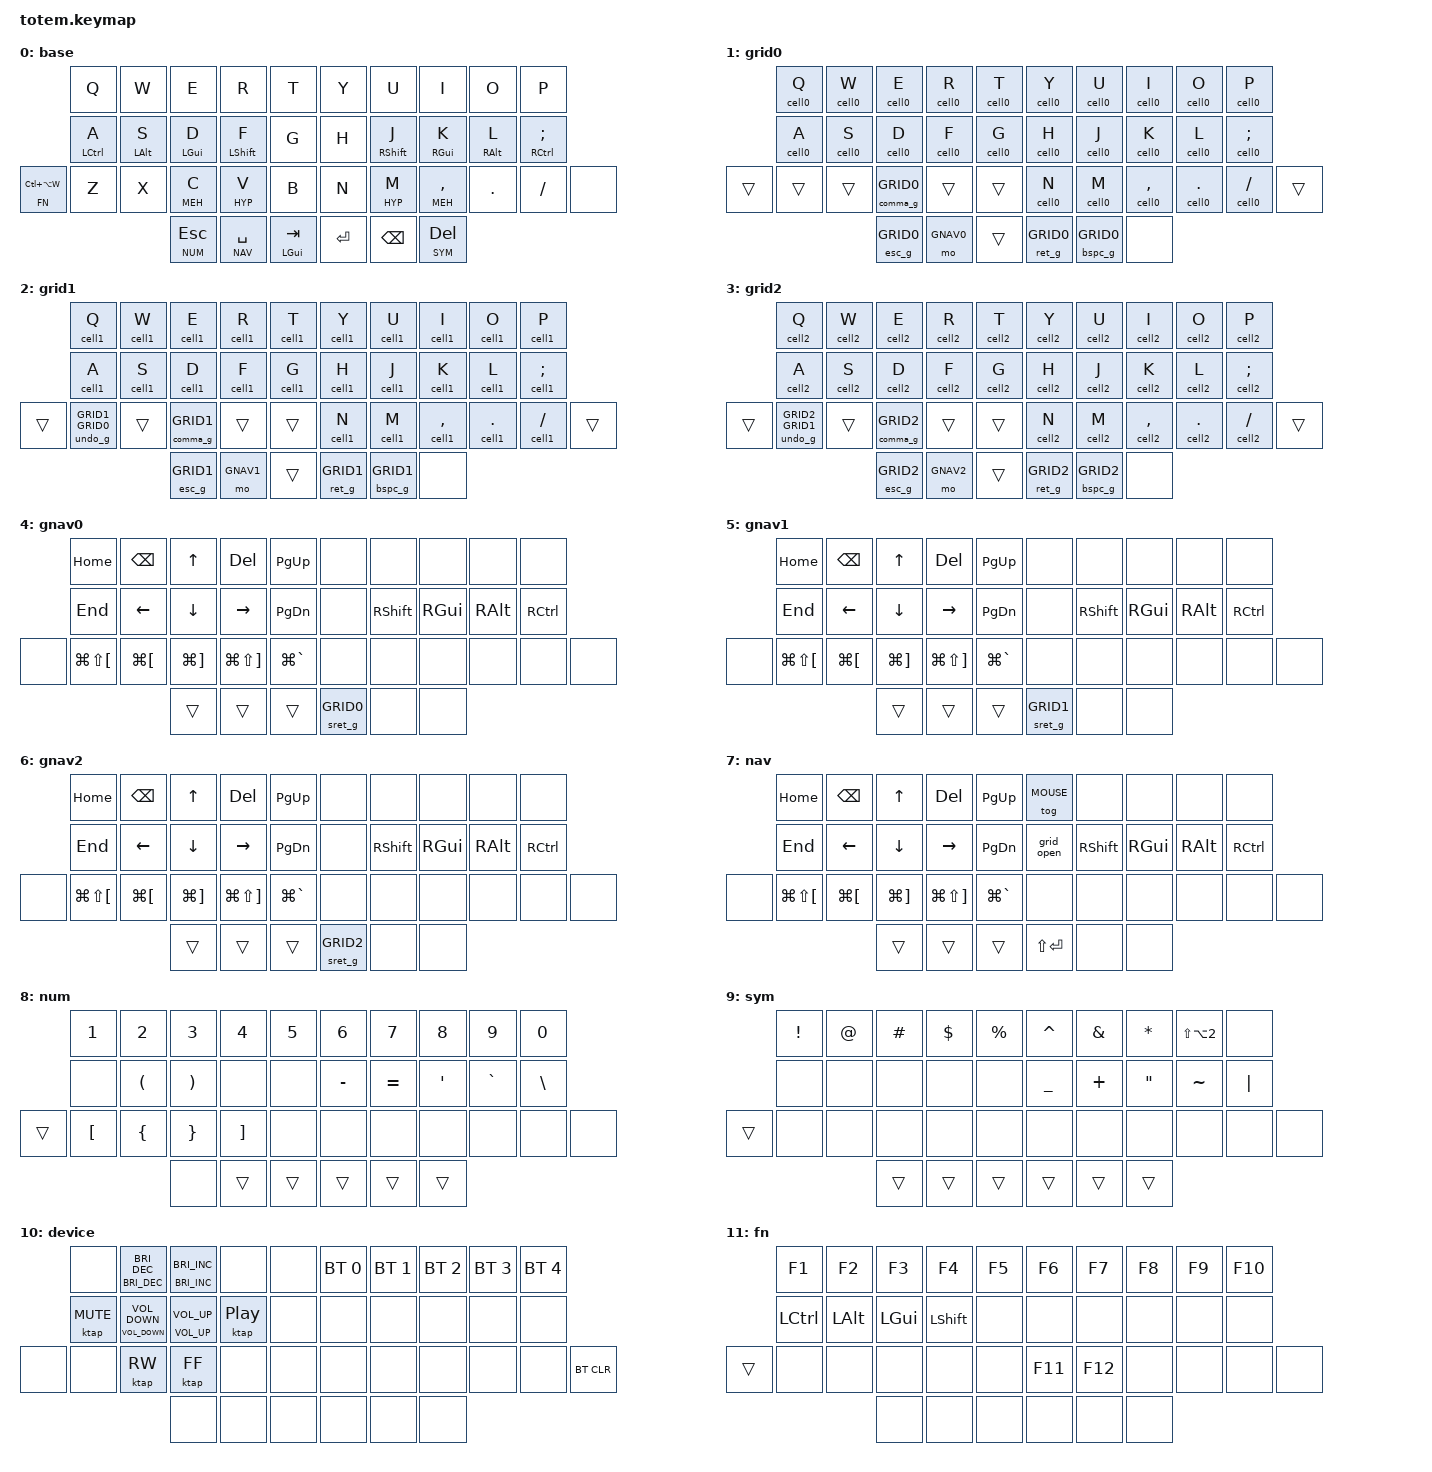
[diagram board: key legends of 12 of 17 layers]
//
//                                                        ▀▀▀▀▀     ▀▀▀▀▀          ▀▀█▀▀
//                                                        ▄▀▀▀▄  ▄  ▄▀▀▀▄  ▄  ▄▀▀▀▄  █  ▄▀▀▀▄
//                                                        █   █  █  █   █  █  █   █  █  █   █
//                                                         ▀▀▀   █   ▀▀▀   █   ▀▀▀   ▀   ▀▀▀
//                                                               █      ▄▄▄█▄▄▄    █   █
//                                                               ▀      █  █  █     █▄█
//                                                             ▀▀▀▀▀    █  █  █      ▀
//                                                                      ▀  ▀  ▀
//
// ▄▄▄▄▄▄▄▄▄▄▄▄▄▄▄▄▄▄▄▄▄▄▄▄▄▄▄▄▄▄▄▄▄▄▄▄▄▄▄▄▄▄▄▄▄▄▄▄▄▄▄▄▄▄▄▄▄▄▄▄▄▄▄▄▄▄▄▄▄▄▄▄▄▄▄▄▄▄▄▄▄▄▄▄▄▄▄▄▄▄▄▄▄▄▄▄▄▄▄▄▄▄▄▄▄▄▄▄▄▄▄▄▄▄▄▄▄▄▄▄▄▄▄▄▄▄▄▄▄▄▄▄▄▄▄▄▄▄▄▄▄▄▄▄▄▄▄▄▄

#include <behaviors.dtsi>
#include <dt-bindings/zmk/bt.h>
#include <dt-bindings/zmk/keys.h>
#include <dt-bindings/zmk/modifiers.h>

// Pointer speed. Firmware default is 600, which crawls; scroll's default 10
// was too slow on-device and 25 too fast.
#define ZMK_POINTING_DEFAULT_MOVE_VAL 1500
#define ZMK_POINTING_DEFAULT_SCRL_VAL 16
#include <dt-bindings/zmk/pointing.h>
#include <zephyr/dt-bindings/input/input-event-codes.h>
#include <input/processors.dtsi>

#define BASE  0
#define GRID0 1
#define GRID1 2
#define GRID2 3
#define GNAV0 4
#define GNAV1 5
#define GNAV2 6
#define NAV   7
#define NUM   8
#define SYM   9
#define DEV   10
#define FN    11
#define ACCENT 12
#define MOUSE   13
#define PRECISE 14
#define SCROLL  15
#define FAST    16

// Hyper = cmd+ctrl+alt+shift, Meh = ctrl+alt+shift.
// No app claims these, so they are safe for global hotkeys.
#define HYP LS(LC(LA(LGUI)))
#define MEH LS(LC(LALT))

// TOTEM key positions, 0-37, in keymap order.
#define KEYS_L  0  1  2  3  4 10 11 12 13 14 20 21 22 23 24 25
#define KEYS_R  5  6  7  8  9 15 16 17 18 19 26 27 28 29 30 31
#define THUMBS 32 33 34 35 36 37

&mt {
    flavor = "balanced";
    tapping-term-ms = <200>;
    // 300 gives an easy tap-then-hold window for auto-repeating tab
    // (cmd+tab cycling). Only the tab thumb uses &mt.
    quick-tap-ms = <300>;
};

// Ramp to full pointer speed over half a second, so a short tap nudges a few
// pixels and a held key crosses the screen. exponent 1 = linear ramp.
// &msc is left at its defaults, which already do not accelerate.
&mmv {
    time-to-max-speed-ms = <500>;
    acceleration-exponent = <1>;
};

// Fast is a scaler on the pointer's event stream, not a set of faster keys:
// holding the fast thumb doubles whatever &mmv is already emitting, so it
// engages mid-hold -- press fast while moving and the cursor speeds up
// instantly, release and it slows. (A key's binding is locked at press time,
// so the old separate-bindings fast only applied to re-presses.)
&mmv_input_listener {
    fast {
        layers = <FAST>;
        input-processors = <&zip_xy_scaler 2 1>;
    };
};

/ {
    behaviors {
        // A second pointer instance with acceleration switched off, used only
        // by the precise tier: a ramped "precise" barely moves on a tap, so
        // its 150 must land on the first report. Fast is not a binding at all
        // anymore -- it is the x2 scaler on &mmv_input_listener above.
        // exponent 0 makes time-to-max-speed-ms inert; it matches the shape
        // ZMK ships for &msc.
        mmv_flat: mmv_flat {
            compatible = "zmk,behavior-input-two-axis";
            #binding-cells = <1>;
            x-input-code = <INPUT_REL_X>;
            y-input-code = <INPUT_REL_Y>;
            time-to-max-speed-ms = <300>;
            acceleration-exponent = <0>;
        };

        // Mouse layer's space thumb: tap is a left click that stays in mouse
        // mode, hold is the scroll layer. hold-preferred so scrolling with
        // e/s/d/f engages immediately; only a lone crisp tap clicks.
        click_scroll: click_scroll {
            compatible = "zmk,behavior-hold-tap";
            #binding-cells = <2>;
            flavor = "hold-preferred";
            tapping-term-ms = <200>;
            bindings = <&mo>, <&mkp>;
        };

        // Mouse layer's esc thumb: tap exits to base (like Esc ends a neru
        // mode), hold is the precise tier. hold-preferred so moving with
        // e/s/d/f while held resolves precise immediately.
        exit_precise: exit_precise {
            compatible = "zmk,behavior-hold-tap";
            #binding-cells = <2>;
            flavor = "hold-preferred";
            tapping-term-ms = <200>;
            bindings = <&mo>, <&to>;
        };

        // Timeless home row mods, per urob / ZMK docs.
        // A mod only fires on cross-hand or thumb follow-ups, and never
        // mid-typing-stream. Same-hand rolls always resolve as taps.
        hml: home_row_mod_left {
            compatible = "zmk,behavior-hold-tap";
            #binding-cells = <2>;
            flavor = "balanced";
            tapping-term-ms = <280>;
            quick-tap-ms = <175>;
            require-prior-idle-ms = <100>;
            bindings = <&kp>, <&kp>;
            hold-trigger-key-positions = <KEYS_R THUMBS>;
            hold-trigger-on-release;
        };

        hmr: home_row_mod_right {
            compatible = "zmk,behavior-hold-tap";
            #binding-cells = <2>;
            flavor = "balanced";
            tapping-term-ms = <280>;
            quick-tap-ms = <175>;
            require-prior-idle-ms = <100>;
            bindings = <&kp>, <&kp>;
            hold-trigger-key-positions = <KEYS_L THUMBS>;
            hold-trigger-on-release;
        };

        // One step per press however long it is held; tap then press-and-hold
        // within quick-tap-ms keeps the key down so macOS repeats it. A tap
        // releases before tapping-term-ms, which must stay below macOS
        // InitialKeyRepeat (180 ms) or a slow tap repeats.
        tap_rep: tap_rep {
            compatible = "zmk,behavior-hold-tap";
            #binding-cells = <2>;
            flavor = "tap-preferred";
            tapping-term-ms = <150>;
            quick-tap-ms = <300>;
            bindings = <&ktap>, <&kp>;
        };
    };

    // A two-axis behavior emits movement onto its own virtual input device;
    // without a listener routing that device into the HID pipeline the events
    // go nowhere and the keys silently do nothing -- precise/fast pressed
    // fine and moved nothing. ZMK pairs its built-in &mmv with exactly this
    // node (app/dts/behaviors/mouse_move.dtsi); a second instance needs its
    // own.
    mmv_flat_input_listener {
        compatible = "zmk,input-listener";
        device = <&mmv_flat>;
    };

    macros {
        // Click and leave the pointer layer in one tap. This is the mouse
        // layer's default right-thumb click, mirroring neru's own default,
        // Space = ["action left_click", "idle"]. Staying in mode is the
        // exception, reached by holding scroll, the left thumb's middle
        // position (see the scroll layer, which overrides these three
        // positions back to a plain, non-exiting &mkp) -- neru's own
        // exception is the same shape, Shift+Space = "action left_click"
        // with no idle. Release before the layer change, or the button
        // sticks.
        lclk_exit: lclk_exit {
            compatible = "zmk,behavior-macro";
            #binding-cells = <0>;
            bindings = <&macro_tap &mkp LCLK>, <&macro_tap &to BASE>;
        };

        rclk_exit: rclk_exit {
            compatible = "zmk,behavior-macro";
            #binding-cells = <0>;
            bindings = <&macro_tap &mkp RCLK>, <&macro_tap &to BASE>;
        };

        mclk_exit: mclk_exit {
            compatible = "zmk,behavior-macro";
            #binding-cells = <0>;
            bindings = <&macro_tap &mkp MCLK>, <&macro_tap &to BASE>;
        };

        // Fixed-length tap whatever the physical hold time. macOS auto-repeats
        // media keys held past InitialKeyRepeat (180 ms here), and a repeated
        // mute or play/pause toggles straight back.
        ktap: ktap {
            compatible = "zmk,behavior-macro-one-param";
            #binding-cells = <1>;
            wait-ms = <0>;
            tap-ms = <30>;
            bindings = <&macro_param_1to1>, <&macro_tap &kp MACRO_PLACEHOLDER>;
        };

        // Firmware-tracked neru grid, as a depth ladder: GRID0/1/2 mirror the
        // grid's selection depth. Cell letters step up a level; the 3rd press
        // matches neru's auto-click+exit and drops everything. z walks back
        // down (neru binds z = undo one level). Esc / ret / bspc / comma
        // close from any level. Desync paths (nav shift+click, tab-tap undo,
        // trackpad clicks, manual V+H trigger) recover with one Esc tap.
        cell0: cell0 {
            compatible = "zmk,behavior-macro-one-param";
            #binding-cells = <1>;
            wait-ms = <0>;
            tap-ms = <5>;
            bindings = <&macro_param_1to1>, <&kp MACRO_PLACEHOLDER>, <&tog GRID0>, <&tog GRID1>;
        };

        cell1: cell1 {
            compatible = "zmk,behavior-macro-one-param";
            #binding-cells = <1>;
            wait-ms = <0>;
            tap-ms = <5>;
            bindings = <&macro_param_1to1>, <&kp MACRO_PLACEHOLDER>, <&tog GRID1>, <&tog GRID2>;
        };

        cell2: cell2 {
            compatible = "zmk,behavior-macro-one-param";
            #binding-cells = <1>;
            wait-ms = <0>;
            tap-ms = <5>;
            bindings = <&macro_param_1to1>, <&kp MACRO_PLACEHOLDER>, <&tog GRID2>;
        };

        esc_g: esc_g {
            compatible = "zmk,behavior-macro-one-param";
            #binding-cells = <1>;
            wait-ms = <0>;
            tap-ms = <5>;
            bindings = <&kp ESC>, <&macro_param_1to1>, <&tog MACRO_PLACEHOLDER>;
        };

        ret_g: ret_g {
            compatible = "zmk,behavior-macro-one-param";
            #binding-cells = <1>;
            wait-ms = <0>;
            tap-ms = <5>;
            bindings = <&kp RET>, <&macro_param_1to1>, <&tog MACRO_PLACEHOLDER>;
        };

        bspc_g: bspc_g {
            compatible = "zmk,behavior-macro-one-param";
            #binding-cells = <1>;
            wait-ms = <0>;
            tap-ms = <5>;
            bindings = <&kp BSPC>, <&macro_param_1to1>, <&tog MACRO_PLACEHOLDER>;
        };

        // the hop: close neru, land in firmware mouse mode -- and back.
        comma_g: comma_g {
            compatible = "zmk,behavior-macro-one-param";
            #binding-cells = <1>;
            wait-ms = <0>;
            tap-ms = <5>;
            bindings = <&kp ESC>, <&macro_param_1to1>, <&tog MACRO_PLACEHOLDER>, <&tog MOUSE>;
        };

        undo_g: undo_g {
            compatible = "zmk,behavior-macro-two-param";
            #binding-cells = <2>;
            wait-ms = <0>;
            tap-ms = <5>;
            bindings = <&kp Z>, <&macro_param_1to1>, <&tog MACRO_PLACEHOLDER>, <&macro_param_2to1>, <&tog MACRO_PLACEHOLDER>;
        };

        // shift+click that the ladder can see: LS(RET) plus the level drop.
        sret_g: sret_g {
            compatible = "zmk,behavior-macro-one-param";
            #binding-cells = <1>;
            wait-ms = <0>;
            tap-ms = <5>;
            bindings = <&kp LS(RET)>, <&macro_param_1to1>, <&tog MACRO_PLACEHOLDER>;
        };

        grid_open: grid_open {
            compatible = "zmk,behavior-macro";
            #binding-cells = <0>;
            wait-ms = <0>;
            tap-ms = <5>;
            bindings = <&kp LS(LC(LA(LG(H))))>, <&tog GRID0>;
        };

        mouse_to_grid: mouse_to_grid {
            compatible = "zmk,behavior-macro";
            #binding-cells = <0>;
            wait-ms = <0>;
            tap-ms = <5>;
            bindings = <&tog MOUSE>, <&kp LS(LC(LA(LG(H))))>, <&tog GRID0>;
        };

        // Drag lock. macro_press holds the button without releasing it, so both
        // hands stay free to move and scroll mid-drag; drag_off drops it. Only
        // worth reaching for on long drags -- holding the LCLK thumb and moving
        // with the same hand's fingers is a real drag already.
        drag_on: drag_on {
            compatible = "zmk,behavior-macro";
            #binding-cells = <0>;
            bindings = <&macro_press &mkp LCLK>;
        };

        drag_off: drag_off {
            compatible = "zmk,behavior-macro";
            #binding-cells = <0>;
            bindings = <&macro_release &mkp LCLK>;
        };

        // macOS dead keys via option (e=acute, `=grave, i=circumflex, u=trema).
        // Needs keyboard type = ANSI, else option+` sends a section sign.
        fr_e_acute: fr_e_acute {
            compatible = "zmk,behavior-macro";
            #binding-cells = <0>;
            bindings = <&macro_tap &kp LA(E)>, <&macro_tap &kp E>;
        };

        fr_e_grave: fr_e_grave {
            compatible = "zmk,behavior-macro";
            #binding-cells = <0>;
            bindings = <&macro_tap &kp LA(GRAVE)>, <&macro_tap &kp E>;
        };

        fr_a_grave: fr_a_grave {
            compatible = "zmk,behavior-macro";
            #binding-cells = <0>;
            bindings = <&macro_tap &kp LA(GRAVE)>, <&macro_tap &kp A>;
        };

        fr_u_grave: fr_u_grave {
            compatible = "zmk,behavior-macro";
            #binding-cells = <0>;
            bindings = <&macro_tap &kp LA(GRAVE)>, <&macro_tap &kp U>;
        };

        fr_circumflex: fr_circumflex {
            compatible = "zmk,behavior-macro";
            #binding-cells = <0>;
            bindings = <&macro_tap &kp LA(I)>;
        };

        fr_trema: fr_trema {
            compatible = "zmk,behavior-macro";
            #binding-cells = <0>;
            bindings = <&macro_tap &kp LA(U)>;
        };
    };

    combos {
        compatible = "zmk,combos";

        // F + J together -> caps lock. Base layer only, so it cannot fire
        // while a layer is held. Short timeout to avoid catching fast typing.
        combo_caps {
            timeout-ms = <40>;
            require-prior-idle-ms = <120>;
            key-positions = <13 16>;   // F and J
            bindings = <&kp CAPS>;
            layers = <BASE>;
        };

        // z + x -> sticky accent layer. Not a digraph, both keys plain.
        combo_accent {
            timeout-ms = <40>;
            require-prior-idle-ms = <120>;
            key-positions = <21 22>;   // Z and X
            bindings = <&sl ACCENT>;
            layers = <BASE>;
        };
    };

    keymap {
        compatible = "zmk,keymap";

        // Mods, weakest finger outward: ctrl - alt - cmd - shift
        // Cmd sits on the middle finger because it is the most used
        // modifier on macOS. Ctrl is on the pinky because it is the least.
        // num key taps ctrl+alt+w for Wispr Flow (its hotkey caps at 3 keys).
        base {
            bindings = <
        &kp Q         &kp W        &kp E        &kp R         &kp T      &kp Y      &kp U         &kp I        &kp O        &kp P
        &hml LCTRL A  &hml LALT S  &hml LGUI D  &hml LSHFT F  &kp G      &kp H      &hmr RSHFT J  &hmr RGUI K  &hmr RALT L  &hmr RCTRL SEMI
&lt FN LC(LA(W))  &kp Z   &kp X        &hml MEH C   &hml HYP V    &kp B      &kp N      &hmr HYP M    &hmr MEH COMMA &kp DOT    &kp FSLH        &none
                                   &lt NUM ESC   &lt NAV SPACE  &mt LGUI TAB &kp RET    &kp BSPC      &lt SYM DEL
            >;
        };

        // Depth ladder tracking neru's grid, below nav in priority. Cell
        // letters advance a level and the 3rd press (= neru's auto-click)
        // drops everything back to base. z walks down a level (neru undo);
        // esc / ret / bspc / comma close from any depth; comma lands in
        // firmware mouse mode. Space still holds nav through these, so
        // space+esdf scroll and space+ret shift+click keep working.
        grid0 {
            bindings = <
        &cell0 Q   &cell0 W   &cell0 E   &cell0 R   &cell0 T      &cell0 Y   &cell0 U   &cell0 I   &cell0 O   &cell0 P
        &cell0 A   &cell0 S   &cell0 D   &cell0 F   &cell0 G      &cell0 H   &cell0 J   &cell0 K   &cell0 L   &cell0 SEMI
&trans  &trans     &trans      &comma_g GRID0   &trans   &trans      &cell0 N   &cell0 M   &cell0 COMMA  &cell0 DOT  &cell0 FSLH  &trans
                              &esc_g GRID0  &mo GNAV0  &trans      &ret_g GRID0  &bspc_g GRID0  &none
            >;
        };

        grid1 {
            bindings = <
        &cell1 Q   &cell1 W   &cell1 E   &cell1 R   &cell1 T      &cell1 Y   &cell1 U   &cell1 I   &cell1 O   &cell1 P
        &cell1 A   &cell1 S   &cell1 D   &cell1 F   &cell1 G      &cell1 H   &cell1 J   &cell1 K   &cell1 L   &cell1 SEMI
&trans  &undo_g GRID1 GRID0  &trans      &comma_g GRID1   &trans   &trans      &cell1 N   &cell1 M   &cell1 COMMA  &cell1 DOT  &cell1 FSLH  &trans
                              &esc_g GRID1  &mo GNAV1  &trans      &ret_g GRID1  &bspc_g GRID1  &none
            >;
        };

        grid2 {
            bindings = <
        &cell2 Q   &cell2 W   &cell2 E   &cell2 R   &cell2 T      &cell2 Y   &cell2 U   &cell2 I   &cell2 O   &cell2 P
        &cell2 A   &cell2 S   &cell2 D   &cell2 F   &cell2 G      &cell2 H   &cell2 J   &cell2 K   &cell2 L   &cell2 SEMI
&trans  &undo_g GRID2 GRID1  &trans      &comma_g GRID2   &trans   &trans      &cell2 N   &cell2 M   &cell2 COMMA  &cell2 DOT  &cell2 FSLH  &trans
                              &esc_g GRID2  &mo GNAV2  &trans      &ret_g GRID2  &bspc_g GRID2  &none
            >;
        };

        // nav mirror while grid depth 0 is active: same arrows/pages/mods,
        // but ret drops the ladder with its shift+click, and the mouse toggle
        // and grid trigger are blanked (both would ghost the ladder).
        gnav0 {
            bindings = <
             &kp HOME     &kp BACKSPACE  &kp UP     &kp DELETE  &kp PG_UP     &none  &none  &none  &none  &none
             &kp END      &kp LEFT       &kp DOWN   &kp RIGHT   &kp PG_DN     &none  &kp RSHFT  &kp RGUI  &kp RALT  &kp RCTRL
&none        &kp LG(LS(LBKT)) &kp LG(LBKT) &kp LG(RBKT) &kp LG(LS(RBKT)) &kp LG(GRAVE)  &none  &none      &none     &none     &none      &none
                                         &trans     &trans      &trans        &sret_g GRID0  &none      &none
            >;
        };

        // nav mirror while grid depth 1 is active: same arrows/pages/mods,
        // but ret drops the ladder with its shift+click, and the mouse toggle
        // and grid trigger are blanked (both would ghost the ladder).
        gnav1 {
            bindings = <
             &kp HOME     &kp BACKSPACE  &kp UP     &kp DELETE  &kp PG_UP     &none  &none  &none  &none  &none
             &kp END      &kp LEFT       &kp DOWN   &kp RIGHT   &kp PG_DN     &none  &kp RSHFT  &kp RGUI  &kp RALT  &kp RCTRL
&none        &kp LG(LS(LBKT)) &kp LG(LBKT) &kp LG(RBKT) &kp LG(LS(RBKT)) &kp LG(GRAVE)  &none  &none      &none     &none     &none      &none
                                         &trans     &trans      &trans        &sret_g GRID1  &none      &none
            >;
        };

        // nav mirror while grid depth 2 is active: same arrows/pages/mods,
        // but ret drops the ladder with its shift+click, and the mouse toggle
        // and grid trigger are blanked (both would ghost the ladder).
        gnav2 {
            bindings = <
             &kp HOME     &kp BACKSPACE  &kp UP     &kp DELETE  &kp PG_UP     &none  &none  &none  &none  &none
             &kp END      &kp LEFT       &kp DOWN   &kp RIGHT   &kp PG_DN     &none  &kp RSHFT  &kp RGUI  &kp RALT  &kp RCTRL
&none        &kp LG(LS(LBKT)) &kp LG(LBKT) &kp LG(RBKT) &kp LG(LS(RBKT)) &kp LG(GRAVE)  &none  &none      &none     &none     &none      &none
                                         &trans     &trans      &trans        &sret_g GRID2  &none      &none
            >;
        };

        // Left hand keeps arrows usable one-handed with the right hand on
        // the trackpad; right home row carries plain mods for cmd+arrow.
        // x/c = history back/forward, v/b = prev/next tab. Device reuses
        // x/c for rewind/fast-forward.
        //
        // h toggles the pointer layer, which is a mode, not a hold. The neru
        // grid is launched by typing its hyper+h hotkey directly: hold v
        // (hyper) + h. Cross-hand, so the home-row hold resolves; m (the
        // other hyper) is same-hand with h and will not.
        //
        // The ret thumb sends shift+enter: with the grid open, plain thumbs
        // click-and-exit (neru binds Enter/Backspace), and holding this nav
        // thumb + ret is shift+click (neru injects the shift via --modifier).
        // cmd+click is the tab thumb's cmd mod-tap held + plain ret.
        nav {
            bindings = <
             &kp HOME     &kp BACKSPACE  &kp UP     &kp DELETE  &kp PG_UP     &tog MOUSE  &none  &none  &none  &none
             &kp END      &kp LEFT       &kp DOWN   &kp RIGHT   &kp PG_DN     &grid_open   &kp RSHFT  &kp RGUI  &kp RALT  &kp RCTRL
&none        &kp LG(LS(LBKT)) &kp LG(LBKT) &kp LG(RBKT) &kp LG(LS(RBKT)) &kp LG(GRAVE)  &none  &none      &none     &none     &none      &none
                                         &trans     &trans      &trans        &kp LS(RET)  &none  &none
            >;
        };

        // Numbers across the top row like a normal keyboard; qwerty's
        // punctuation strip (- = ' ` \) on the right home row in qwerty
        // order. Brackets keep their spots; { } slide down beside ( ) since
        // the numbers evicted them; euro next door. Thumbs transparent so
        // ret/bspc work mid-number. Mod chords (zoom cmd+=, screenshot
        // shift+cmd+4) pre-hold the base home-row mods, then num.
        num {
            bindings = <
           &kp N1         &kp N2                &kp N3                 &kp N4            &kp N5            &kp N6      &kp N7    &kp N8     &kp N9    &kp N0
           &none          &kp LEFT_PARENTHESIS  &kp RIGHT_PARENTHESIS  &none             &none             &kp MINUS   &kp EQUAL &kp APOS   &kp GRAVE &kp BSLH
&trans     &kp LBKT       &kp LEFT_BRACE        &kp RIGHT_BRACE        &kp RBKT          &none             &none       &none     &none      &none     &none     &none
                                                &none                  &trans            &trans            &trans      &trans    &trans
            >;
        };

        // Shifted mirror of num, same positions: sym(key) = shift(num(key)),
        // no exceptions. Own thumb-hold on Del (tap Del, hold Sym),
        // independent of whether num is also held.
        sym {
            bindings = <
        &kp EXCLAMATION &kp AT_SIGN     &kp HASH  &kp DOLLAR  &kp PERCENT    &kp CARET  &kp AMPERSAND  &kp ASTERISK  &kp LS(LA(N2))  &none
        &none      &none            &none             &none              &none    &kp UNDERSCORE   &kp PLUS   &kp DOUBLE_QUOTES  &kp TILDE  &kp PIPE
&trans     &none      &none            &none             &none              &none    &none            &none      &none              &none      &none      &none
                                     &trans           &trans            &trans   &trans           &trans          &trans
            >;
        };

        device {
            bindings = <
       &none         &tap_rep C_BRIGHTNESS_DEC C_BRIGHTNESS_DEC  &tap_rep C_BRIGHTNESS_INC C_BRIGHTNESS_INC  &none               &none    &bt BT_SEL 0  &bt BT_SEL 1  &bt BT_SEL 2  &bt BT_SEL 3  &bt BT_SEL 4
       &ktap K_MUTE  &tap_rep C_VOLUME_DOWN C_VOLUME_DOWN        &tap_rep C_VOLUME_UP C_VOLUME_UP            &ktap C_PLAY_PAUSE  &none    &none         &none         &none         &none         &none
&none  &none         &ktap C_RW              &ktap C_FF              &none               &none    &none         &none         &none         &none         &none         &bt BT_CLR
                                         &none                 &none             &none    &none         &none         &none
            >;
        };

        // Function keys, held with the left outer pinky. Left home row carries
        // plain mods so cmd+f-key and shift+f-key work while the layer is held.
        fn {
            bindings = <
        &kp F1     &kp F2     &kp F3     &kp F4     &kp F5      &kp F6  &kp F7  &kp F8  &kp F9  &kp F10
        &kp LCTRL  &kp LALT   &kp LGUI   &kp LSHFT  &none       &none   &none   &none   &none   &none
&trans  &none      &none      &none      &none      &none       &kp F11 &kp F12 &none   &none   &none   &none
                              &none      &none      &none       &none   &none   &none
            >;
        };

        // Reached via the z+x sticky combo: one chord, one tap, no holds.
        // i/y arm the circumflex/trema dead keys instead of a fixed letter.
        accent {
            bindings = <
&trans       &trans  &fr_e_acute  &trans      &trans   &fr_trema  &fr_u_grave  &fr_circumflex  &trans  &trans
&fr_a_grave  &trans  &fr_e_grave  &trans      &trans   &trans     &trans       &trans          &trans  &trans
&trans       &trans  &trans       &kp LA(C)   &trans   &trans     &trans       &trans          &trans  &trans  &trans  &trans
                                  &trans      &trans   &trans     &trans       &trans          &trans
            >;
        };

        // Firmware pointer, arranged after miryoku's mouse layer: one hand owns
        // the pointer, the other owns the modifiers, so every modified action
        // is a cross-hand chord and nothing contorts.
        //
        // Miryoku's rule is that mouse movement mirrors cursor navigation, and
        // nav here is left-handed, so the pointer is too: move on e/s/d/f, the
        // exact inverted-T nav uses for arrows.
        //
        // Clicks are on the right thumbs, left/right/middle outward from
        // center: left click nearest the fingers since it is the one held for
        // drag, middle click outermost since it is rarest. They exit the
        // layer by default -- aim, click, done, mirroring neru's own default
        // (Space = ["action left_click", "idle"]). Holding scroll (the left
        // thumb's middle position) and clicking is the exception that stays
        // in mode, mirroring neru's Shift+Space (click with no idle) -- see
        // the scroll layer, which overrides these three positions back to a
        // plain, non-exiting &mkp. Esc is dropped: it was only reachable one
        // thumb at a time anyway, since scroll occupies the thumb Esc used
        // to sit on.
        //
        // Left thumbs are slow / scroll / fast, one hold each -- a single
        // thumb only ever does one job at a time, so scroll lives on its own
        // thumb rather than a separate key on row3. See precise/scroll/fast
        // below for why each is a held layer rather than a modifier.
        //
        // Right home row is plain mods, same order as base. That is what makes
        // ctrl+scroll (zoom in Figma and browsers), shift+click, and cmd+click
        // work without the pointer hand leaving home position.
        //
        // Miryoku holds this layer with an opposite-hand thumb; all three left
        // thumbs are already committed here, so it stays a toggle off nav's h,
        // exited from the same position.
        mouse {
            bindings = <
        &none      &none           &mmv MOVE_UP    &none            &none      &none    &none    &none     &none     &none
        &none      &mmv MOVE_LEFT  &mmv MOVE_DOWN  &mmv MOVE_RIGHT  &none      &none    &kp RSHFT &kp RGUI  &kp RALT  &kp RCTRL
&trans  &drag_on   &drag_off       &mouse_to_grid  &none            &none      &none    &none     &none     &none     &none      &none
                                   &exit_precise PRECISE BASE  &click_scroll SCROLL LCLK  &mo FAST   &lclk_exit  &rclk_exit  &mclk_exit
            >;
        };

        // Speed tiers on e/s/d/f, held from the left thumbs' outer two
        // positions. Held layers rather than mod-morphs for the same reason
        // as scroll: a real modifier would cost mod+drag.
        //
        // &mmv_flat, not &mmv: no ramp, so the value lands on the first
        // report. That is the whole point of a tier -- a ramped tier is just
        // the normal key with a different ceiling.
        precise {
            bindings = <
        &trans  &trans                  &mmv_flat MOVE_Y(-150)   &trans                  &trans   &trans  &trans  &trans  &trans  &trans
        &trans  &mmv_flat MOVE_X(-150)  &mmv_flat MOVE_Y(150)    &mmv_flat MOVE_X(150)   &trans   &trans  &trans  &trans  &trans  &trans
&trans  &trans  &trans                  &trans                   &trans                  &trans   &trans  &trans  &trans  &trans  &trans  &trans
                                        &trans                   &trans                  &trans   &trans  &trans  &trans
            >;
        };

        // Held from the left thumb's middle position -- physically between
        // precise and fast, but this is not a speed tier: e/s/d/f becomes
        // scroll, not a third move speed. It does two jobs on one thumb
        // rather than splitting them across two keys:
        //
        // 1. Scroll on the same e/s/d/f as move. Everything else falls
        //    through, so the mouse layer's mods stay live -- shift+scroll is
        //    still horizontal scroll, ctrl+scroll is still zoom. Page up/down
        //    on t/g, the same column nav uses for its own PG_UP/PG_DN below
        //    UP/DOWN; mouse leaves that column &none, so this is scroll-only.
        //    The SCRL_* bindings are deliberately crossed (the up key sends
        //    SCRL_DOWN, etc.): macOS natural scrolling flips wheel input on
        //    both axes, and this cancels it so keys move the viewport the
        //    way they point.
        //    t/g are page-jump wheel bursts, not &kp PG_UP/PG_DN: PG keys act
        //    on the focused window, wheel events on the window under the
        //    cursor, and everything else in this mode follows the cursor.
        //
        // 2. The right thumbs override back to plain, non-exiting clicks:
        //    hold scroll (you are mid-navigation, finding the thing to
        //    click) and tap a click, and it fires without dropping you out
        //    of mouse mode -- left-thumb hold, right-thumb tap, a genuine
        //    cross-hand chord. A held layer rather than a mod-morph here too:
        //    a morph would need a real HID modifier, disturbing the right
        //    home row's shift/cmd/ctrl/alt click meaning.
        scroll {
            bindings = <
        &trans  &trans            &msc SCRL_DOWN   &trans            &msc MOVE_Y(-120)  &trans  &trans  &trans  &trans  &trans
        &trans  &msc SCRL_RIGHT   &msc SCRL_UP     &msc SCRL_LEFT    &msc MOVE_Y(120)   &trans  &trans  &trans  &trans  &trans
&trans  &trans  &trans            &trans           &trans            &trans      &trans  &trans     &trans     &trans     &trans  &trans
                                  &trans           &trans            &trans      &mkp LCLK  &mkp RCLK  &mkp MCLK
            >;
        };

        // Empty on purpose: fast is the x2 scaler on &mmv_input_listener
        // (see top of file). Holding this layer's thumb is the whole feature.
        fast {
            bindings = <
        &trans  &trans  &trans  &trans  &trans  &trans  &trans  &trans  &trans  &trans
        &trans  &trans  &trans  &trans  &trans  &trans  &trans  &trans  &trans  &trans
&trans  &trans  &trans  &trans  &trans  &trans  &trans  &trans  &trans  &trans  &trans  &trans
                        &trans  &trans  &trans  &trans  &trans  &trans
            >;
        };

        // Spare for adding a layer live in ZMK Studio. Reserved layers are not
        // status-okay, so this does not shift any layer index above.
        extra8 { status = "reserved"; };
    };

    conditional_layers {
        compatible = "zmk,conditional-layers";

        device {
            if-layers = <NAV NUM>;
            then-layer = <DEV>;
        };
    };
};
